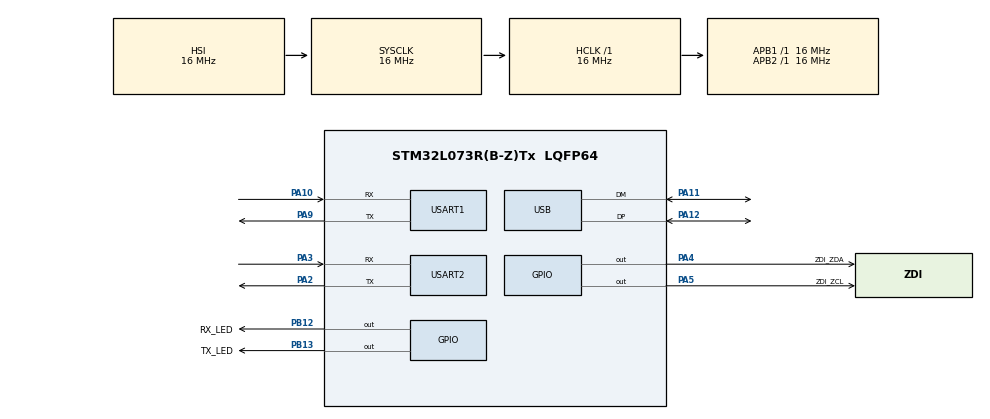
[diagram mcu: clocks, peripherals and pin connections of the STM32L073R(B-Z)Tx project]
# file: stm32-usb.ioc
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Dma.Request0=USART1_RX
Dma.Request1=USART2_RX
Dma.USART1_RX.0.Direction=DMA_PERIPH_TO_MEMORY
Dma.USART1_RX.0.Instance=DMA1_Channel3
Dma.USART1_RX.0.MemDataAlignment=DMA_MDATAALIGN_BYTE
Dma.USART1_RX.0.MemInc=DMA_MINC_ENABLE
Dma.USART1_RX.0.Mode=DMA_CIRCULAR
Dma.USART1_RX.0.PeriphDataAlignment=DMA_PDATAALIGN_BYTE
Dma.USART1_RX.0.PeriphInc=DMA_PINC_DISABLE
Dma.USART1_RX.0.Priority=DMA_PRIORITY_LOW
Dma.USART2_RX.1.Direction=DMA_PERIPH_TO_MEMORY
Dma.USART2_RX.1.Instance=DMA1_Channel5
Dma.USART2_RX.1.MemDataAlignment=DMA_MDATAALIGN_BYTE
Dma.USART2_RX.1.MemInc=DMA_MINC_ENABLE
Dma.USART2_RX.1.Mode=DMA_CIRCULAR
Dma.USART2_RX.1.PeriphDataAlignment=DMA_PDATAALIGN_BYTE
Dma.USART2_RX.1.PeriphInc=DMA_PINC_DISABLE
Dma.USART2_RX.1.Priority=DMA_PRIORITY_LOW
Mcu.Family=STM32L0
Mcu.Name=STM32L073R(B-Z)Tx
Mcu.Package=LQFP64
NVIC.DMA1_Channel2_3_IRQn=true\:0\:0\:false\:false\:true\:false\:true
NVIC.DMA1_Channel4_5_6_7_IRQn=true\:0\:0\:false\:false\:true\:false\:true
NVIC.USART1_IRQn=true\:0\:0\:false\:false\:true\:true\:true
NVIC.USART2_IRQn=true\:0\:0\:false\:false\:true\:true\:true
PA10.Mode=Asynchronous
PA10.Signal=USART1_RX
PA11.Mode=Device
PA11.Signal=USB_DM
PA12.Mode=Device
PA12.Signal=USB_DP
PA13.Mode=Serial_Wire
PA13.Signal=SYS_SWDIO
PA14.Mode=Serial_Wire
PA14.Signal=SYS_SWCLK
PA2.Mode=Asynchronous
PA2.Signal=USART2_TX
PA3.Mode=Asynchronous
PA3.Signal=USART2_RX
PA4.GPIO_Label=ZDI_ZDA
PA4.GPIO_ModeDefaultOutputPP=GPIO_MODE_OUTPUT_OD
PA4.GPIO_Speed=GPIO_SPEED_FREQ_VERY_HIGH
PA4.PinState=GPIO_PIN_SET
PA4.Signal=GPIO_Output
PA5.GPIO_Label=ZDI_ZCL
PA5.GPIO_Speed=GPIO_SPEED_FREQ_VERY_HIGH
PA5.PinState=GPIO_PIN_SET
PA5.Signal=GPIO_Output
PA9.Mode=Asynchronous
PA9.Signal=USART1_TX
PB12.GPIO_Label=RX_LED
PB12.PinState=GPIO_PIN_SET
PB12.Signal=GPIO_Output
PB13.GPIO_Label=TX_LED
PB13.PinState=GPIO_PIN_SET
PB13.Signal=GPIO_Output
ProjectManager.HeapSize=0x200
ProjectManager.StackSize=0x400
ProjectManager.TargetToolchain=STM32CubeIDE
RCC.AHBFreq_Value=16000000
RCC.APB1Freq_Value=16000000
RCC.APB1TimFreq_Value=16000000
RCC.APB2Freq_Value=16000000
RCC.APB2TimFreq_Value=16000000
RCC.HCLKFreq_Value=16000000
RCC.HSE_VALUE=8000000
RCC.HSI16_VALUE=16000000
RCC.HSI48MClockSelection=RCC_USBCLKSOURCE_HSI48
RCC.HSI48_VALUE=48000000
RCC.HSI_VALUE=16000000
RCC.LSE_VALUE=32768
RCC.MSI_VALUE=2097000
RCC.PLLDIV=RCC_PLLDIV_3
RCC.PLLMUL=RCC_PLLMUL_6
RCC.SYSCLKFreq_VALUE=16000000
RCC.SYSCLKSource=RCC_SYSCLKSOURCE_HSI
RCC.VCOOutputFreq_Value=96000000
USART1.VirtualMode-Asynchronous=VM_ASYNC
USART2.VirtualMode-Asynchronous=VM_ASYNC
board=custom

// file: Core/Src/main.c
/* USER CODE BEGIN Header */
/**
  ******************************************************************************
  * @file           : main.c
  * @brief          : Main program body
  ******************************************************************************
  * @attention
  *
  * <h2><center>&copy; Copyright (c) 2021 STMicroelectronics.
  * All rights reserved.</center></h2>
  *
  * This software component is licensed by ST under BSD 3-Clause license,
  * the "License"; You may not use this file except in compliance with the
  * License. You may obtain a copy of the License at:
  *                        opensource.org/licenses/BSD-3-Clause
  *
  ******************************************************************************
  */
/* USER CODE END Header */
#include "main.h"

/* USER CODE BEGIN Includes */
#include "usb_device.h"
#include "ulisp.h"

/* USER CODE END Includes */

UART_HandleTypeDef huart1;
UART_HandleTypeDef huart2;
DMA_HandleTypeDef hdma_usart1_rx;
DMA_HandleTypeDef hdma_usart2_rx;

PCD_HandleTypeDef hpcd_USB_FS;

void SystemClock_Config(void);
static void MX_GPIO_Init(void);
static void MX_DMA_Init(void);
static void MX_USART1_UART_Init(void);
static void MX_USART2_UART_Init(void);
static void MX_USB_PCD_Init(void);

int main(void)
{

  /* MCU Configuration--------------------------------------------------------*/

  /* Reset of all peripherals, Initializes the Flash interface and the Systick. */
  HAL_Init();

  /* Configure the system clock */
  SystemClock_Config();

  /* Initialize all configured peripherals */
  MX_GPIO_Init();
  MX_DMA_Init();
  MX_USART1_UART_Init();
  MX_USART2_UART_Init();
  MX_USB_PCD_Init();
  /* USER CODE BEGIN 2 */
  MX_USB_DEVICE_Init();

  setvbuf(stdin, NULL, _IONBF, 0);
  setvbuf(stdout, NULL, _IONBF, 0);
  setvbuf(stderr, NULL, _IONBF, 0);

  getchar();
  setup(); // uLisp

  /* USER CODE END 2 */

  /* Infinite loop */
  while (1)
  {

    /* USER CODE BEGIN 3 */
	loop(); // uLisp
//	HAL_GPIO_TogglePin(RX_LED_GPIO_Port, RX_LED_Pin);
//	printf("tick\r\n");
//	HAL_Delay(500);
	// TODO get command line from USB CDC3
	// TODO process command
	// TODO transfer output to USB
  }
  /* USER CODE END 3 */
}

void SystemClock_Config(void)
{
  RCC_OscInitTypeDef RCC_OscInitStruct = {0};
  RCC_ClkInitTypeDef RCC_ClkInitStruct = {0};
  RCC_PeriphCLKInitTypeDef PeriphClkInit = {0};

  /** Configure the main internal regulator output voltage
  */
  __HAL_PWR_VOLTAGESCALING_CONFIG(PWR_REGULATOR_VOLTAGE_SCALE1);
  /** Initializes the RCC Oscillators according to the specified parameters
  * in the RCC_OscInitTypeDef structure.
  */
  RCC_OscInitStruct.OscillatorType = RCC_OSCILLATORTYPE_HSI|RCC_OSCILLATORTYPE_HSI48;
  RCC_OscInitStruct.HSIState = RCC_HSI_ON;
  RCC_OscInitStruct.HSICalibrationValue = RCC_HSICALIBRATION_DEFAULT;
  RCC_OscInitStruct.HSI48State = RCC_HSI48_ON;
  RCC_OscInitStruct.PLL.PLLState = RCC_PLL_NONE;
  if (HAL_RCC_OscConfig(&RCC_OscInitStruct) != HAL_OK)
  {
    Error_Handler();
  }
  /** Initializes the CPU, AHB and APB buses clocks
  */
  RCC_ClkInitStruct.ClockType = RCC_CLOCKTYPE_HCLK|RCC_CLOCKTYPE_SYSCLK
                              |RCC_CLOCKTYPE_PCLK1|RCC_CLOCKTYPE_PCLK2;
  RCC_ClkInitStruct.SYSCLKSource = RCC_SYSCLKSOURCE_HSI;
  RCC_ClkInitStruct.AHBCLKDivider = RCC_SYSCLK_DIV1;
  RCC_ClkInitStruct.APB1CLKDivider = RCC_HCLK_DIV1;
  RCC_ClkInitStruct.APB2CLKDivider = RCC_HCLK_DIV1;

  if (HAL_RCC_ClockConfig(&RCC_ClkInitStruct, FLASH_LATENCY_0) != HAL_OK)
  {
    Error_Handler();
  }
  PeriphClkInit.PeriphClockSelection = RCC_PERIPHCLK_USART1|RCC_PERIPHCLK_USART2
                              |RCC_PERIPHCLK_USB;
  PeriphClkInit.Usart1ClockSelection = RCC_USART1CLKSOURCE_PCLK2;
  PeriphClkInit.Usart2ClockSelection = RCC_USART2CLKSOURCE_PCLK1;
  PeriphClkInit.UsbClockSelection = RCC_USBCLKSOURCE_HSI48;
  if (HAL_RCCEx_PeriphCLKConfig(&PeriphClkInit) != HAL_OK)
  {
    Error_Handler();
  }
}

static void MX_USART1_UART_Init(void)
{

  huart1.Instance = USART1;
  huart1.Init.BaudRate = 115200;
  huart1.Init.WordLength = UART_WORDLENGTH_8B;
  huart1.Init.StopBits = UART_STOPBITS_1;
  huart1.Init.Parity = UART_PARITY_NONE;
  huart1.Init.Mode = UART_MODE_TX_RX;
  huart1.Init.HwFlowCtl = UART_HWCONTROL_NONE;
  huart1.Init.OverSampling = UART_OVERSAMPLING_16;
  huart1.Init.OneBitSampling = UART_ONE_BIT_SAMPLE_DISABLE;
  huart1.AdvancedInit.AdvFeatureInit = UART_ADVFEATURE_NO_INIT;
  if (HAL_UART_Init(&huart1) != HAL_OK)
  {
    Error_Handler();
  }
  /* USER CODE BEGIN USART1_Init 2 */
//  UART_DIV_SAMPLING16(HAL_RCC_GetPCLK1Freq(), 115200);

  /* USER CODE END USART1_Init 2 */

}

static void MX_USART2_UART_Init(void)
{

  huart2.Instance = USART2;
  huart2.Init.BaudRate = 115200;
  huart2.Init.WordLength = UART_WORDLENGTH_8B;
  huart2.Init.StopBits = UART_STOPBITS_1;
  huart2.Init.Parity = UART_PARITY_NONE;
  huart2.Init.Mode = UART_MODE_TX_RX;
  huart2.Init.HwFlowCtl = UART_HWCONTROL_NONE;
  huart2.Init.OverSampling = UART_OVERSAMPLING_16;
  huart2.Init.OneBitSampling = UART_ONE_BIT_SAMPLE_DISABLE;
  huart2.AdvancedInit.AdvFeatureInit = UART_ADVFEATURE_NO_INIT;
  if (HAL_UART_Init(&huart2) != HAL_OK)
  {
    Error_Handler();
  }

}

static void MX_USB_PCD_Init(void)
{

  hpcd_USB_FS.Instance = USB;
  hpcd_USB_FS.Init.dev_endpoints = 8;
  hpcd_USB_FS.Init.speed = PCD_SPEED_FULL;
  hpcd_USB_FS.Init.phy_itface = PCD_PHY_EMBEDDED;
  hpcd_USB_FS.Init.low_power_enable = DISABLE;
  hpcd_USB_FS.Init.lpm_enable = DISABLE;
  hpcd_USB_FS.Init.battery_charging_enable = DISABLE;
  if (HAL_PCD_Init(&hpcd_USB_FS) != HAL_OK)
  {
    Error_Handler();
  }

}

static void MX_DMA_Init(void)
{

  /* DMA controller clock enable */
  __HAL_RCC_DMA1_CLK_ENABLE();

  /* DMA interrupt init */
  /* DMA1_Channel2_3_IRQn interrupt configuration */
  HAL_NVIC_SetPriority(DMA1_Channel2_3_IRQn, 0, 0);
  HAL_NVIC_EnableIRQ(DMA1_Channel2_3_IRQn);
  /* DMA1_Channel4_5_6_7_IRQn interrupt configuration */
  HAL_NVIC_SetPriority(DMA1_Channel4_5_6_7_IRQn, 0, 0);
  HAL_NVIC_EnableIRQ(DMA1_Channel4_5_6_7_IRQn);

}

static void MX_GPIO_Init(void)
{
  GPIO_InitTypeDef GPIO_InitStruct = {0};

  /* GPIO Ports Clock Enable */
  __HAL_RCC_GPIOA_CLK_ENABLE();
  __HAL_RCC_GPIOB_CLK_ENABLE();

  /*Configure GPIO pin Output Level */
  HAL_GPIO_WritePin(GPIOA, ZDI_ZDA_Pin|ZDI_ZCL_Pin, GPIO_PIN_SET);

  /*Configure GPIO pin Output Level */
  HAL_GPIO_WritePin(GPIOB, RX_LED_Pin|TX_LED_Pin, GPIO_PIN_SET);

  /*Configure GPIO pin : ZDI_ZDA_Pin */
  GPIO_InitStruct.Pin = ZDI_ZDA_Pin;
  GPIO_InitStruct.Mode = GPIO_MODE_OUTPUT_OD;
  GPIO_InitStruct.Pull = GPIO_NOPULL;
  GPIO_InitStruct.Speed = GPIO_SPEED_FREQ_VERY_HIGH;
  HAL_GPIO_Init(ZDI_ZDA_GPIO_Port, &GPIO_InitStruct);

  /*Configure GPIO pin : ZDI_ZCL_Pin */
  GPIO_InitStruct.Pin = ZDI_ZCL_Pin;
  GPIO_InitStruct.Mode = GPIO_MODE_OUTPUT_PP;
  GPIO_InitStruct.Pull = GPIO_NOPULL;
  GPIO_InitStruct.Speed = GPIO_SPEED_FREQ_VERY_HIGH;
  HAL_GPIO_Init(ZDI_ZCL_GPIO_Port, &GPIO_InitStruct);

  /*Configure GPIO pins : RX_LED_Pin TX_LED_Pin */
  GPIO_InitStruct.Pin = RX_LED_Pin|TX_LED_Pin;
  GPIO_InitStruct.Mode = GPIO_MODE_OUTPUT_PP;
  GPIO_InitStruct.Pull = GPIO_NOPULL;
  GPIO_InitStruct.Speed = GPIO_SPEED_FREQ_LOW;
  HAL_GPIO_Init(GPIOB, &GPIO_InitStruct);

}

void Error_Handler(void)
{
  __disable_irq();
  while (1)
  {
  }
}

/************************ (C) COPYRIGHT STMicroelectronics *****END OF FILE****/
